# PIC32MZ1024EFK064 register map
Vendor: Microchip
Registers are 32-bit, read-write, reset 0x0 unless marked. A register's access mark holds for its fields unless they carry their own. Addresses are absolute, and some are shared; only a register's first bit layout is shown; [hi:lo] are bit positions; {n}, {i} and the like mark numbered series; 'fields as' and 'values as' point back to an identical list.

## CFG
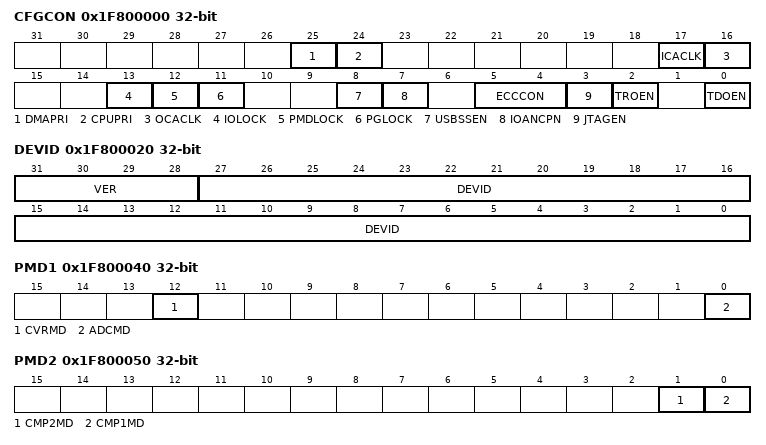
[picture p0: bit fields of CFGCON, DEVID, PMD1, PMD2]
0x1F800000 CFGCON reset not defined — (power-on value ------00------00--000--0x-1100-1)
  [25] DMAPRI, [24] CPUPRI, [17] ICACLK, [16] OCACLK, [13] IOLOCK, [12] PMDLOCK, [11] PGLOCK, [8] USBSSEN, [7] IOANCPN, [5:4] ECCCON, [3] JTAGEN, [2] TROEN, [0] TDOEN
0x1F800020 DEVID reset not defined — (power-on value 0000xxxxxxxxxxxxxxxxxxxxxxxxxxxx)
  [31:28] VER ro, [27:0] DEVID
0x1F800030 SYSKEY
0x1F800040 PMD1
  [12] CVRMD, [0] ADCMD
0x1F800050 PMD2
  [1] CMP2MD, [0] CMP1MD
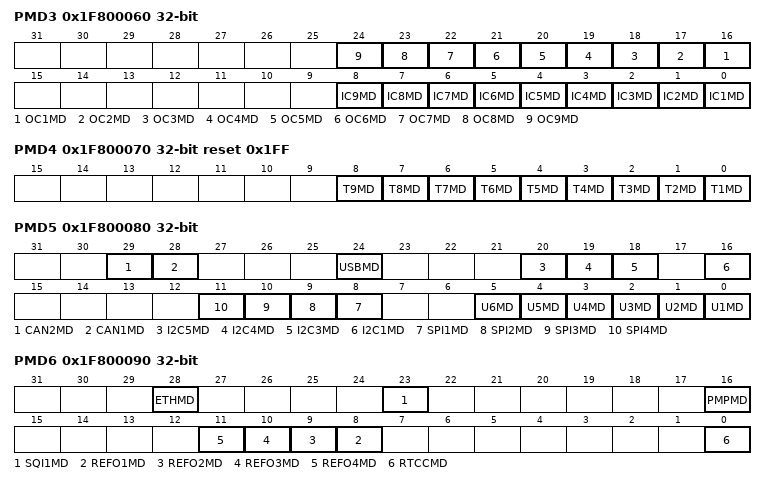
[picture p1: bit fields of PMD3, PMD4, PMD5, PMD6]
0x1F800060 PMD3
  [n+15] OC{n}MD (n=1..9), [n-1] IC{n}MD (n=1..9)
0x1F800070 PMD4 reset 0x1FF
  [n-1] T{n}MD (n=1..9)
0x1F800080 PMD5
  [29] CAN2MD, [28] CAN1MD, [24] USBMD, [20] I2C5MD, [19] I2C4MD, [18] I2C3MD, [16] I2C1MD, [n+7] SPI{n}MD (n=1..4), [n-1] U{n}MD (n=1..6)
0x1F800090 PMD6
  [28] ETHMD, [23] SQI1MD, [16] PMPMD, [n+7] REFO{n}MD (n=1..4), [0] RTCCMD
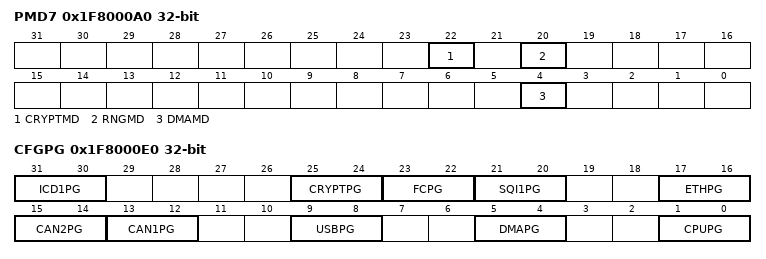
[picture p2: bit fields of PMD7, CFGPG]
0x1F8000A0 PMD7
  [22] CRYPTMD, [20] RNGMD, [4] DMAMD
0x1F8000E0 CFGPG reset not defined — (power-on value xx----000000--000000--00--00--00)
  [31:30] ICD1PG, [25:24] CRYPTPG, [23:22] FCPG, [21:20] SQI1PG, [17:16] ETHPG, [15:14] CAN2PG, [13:12] CAN1PG, [9:8] USBPG, [5:4] DMAPG, [1:0] CPUPG

## NVM
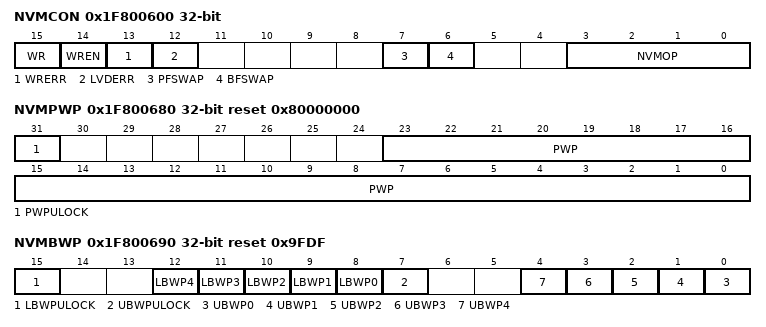
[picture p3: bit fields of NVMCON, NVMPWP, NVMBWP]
0x1F800600 NVMCON reset not defined — (power-on value ----------------0000----0x--0000)
  [15] WR, [14] WREN, [13] WRERR, [12] LVDERR, [7] PFSWAP, [6] BFSWAP, [3:0] NVMOP
0x1F800610 NVMKEY wo
0x1F800620 NVMADDR
{0x1F800630+0x10*i} NVMDATA{i} (i=0..3)
0x1F800670 NVMSRCADDR
0x1F800680 NVMPWP reset 0x80000000
  [31] PWPULOCK, [23:0] PWP
0x1F800690 NVMBWP reset 0x9FDF
  [15] LBWPULOCK, [n+8] LBWP{n} (n=0..4), [7] UBWPULOCK, [n] UBWP{n} (n=0..4)
0x1F8006A0 NVMCON2
  [7:6] SWAPLOCK

## WDT
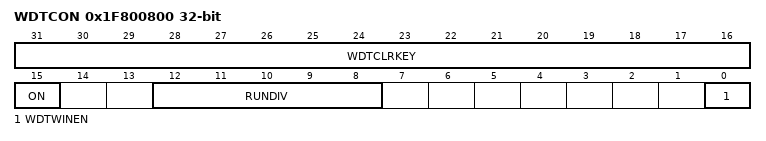
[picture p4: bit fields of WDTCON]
0x1F800800 WDTCON reset not defined — (power-on value 0000000000000000x--xxxxx-------0)
  [31:16] WDTCLRKEY wo, [15] ON, [12:8] RUNDIV ro, [0] WDTWINEN

## DMT
0x1F800A00 DMTCON
  [15] ON
0x1F800A10 DMTPRECLR
  [15:8] STEP1
0x1F800A20 DMTCLR
  [7:0] STEP2
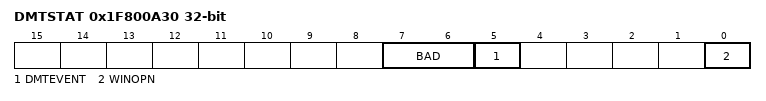
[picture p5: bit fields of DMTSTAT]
0x1F800A30 DMTSTAT ro
  [7:6] BAD, [5] DMTEVENT, [0] WINOPN
0x1F800A40 DMTCNT ro
  [31:0] COUNTER
0x1F800A60 DMTPSCNT ro reset not defined — (power-on value xxxxxxxxxxxxxxxxxxxxxxxxxxxxxxxx)
  [31:0] PSCNT
0x1F800A70 DMTPSINTV ro reset not defined — (power-on value xxxxxxxxxxxxxxxxxxxxxxxxxxxxxxxx)
  [31:0] PSINTV

## RTCC
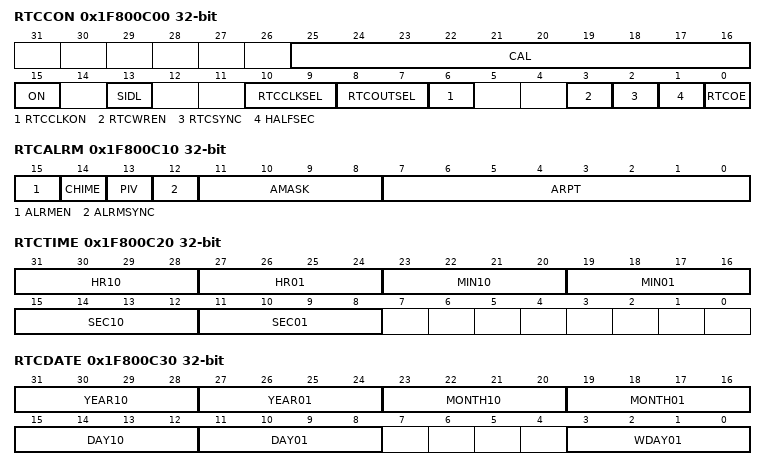
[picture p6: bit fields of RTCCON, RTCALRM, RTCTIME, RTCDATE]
0x1F800C00 RTCCON
  [25:16] CAL, [15] ON, [13] SIDL, [10:9] RTCCLKSEL, [8:7] RTCOUTSEL, [6] RTCCLKON, [3] RTCWREN, [2] RTCSYNC ro, [1] HALFSEC ro, [0] RTCOE
0x1F800C10 RTCALRM
  [15] ALRMEN, [14] CHIME, [13] PIV, [12] ALRMSYNC, [11:8] AMASK, [7:0] ARPT
0x1F800C20 RTCTIME reset not defined — (power-on value 000xxxxxxxxxxxxx0xxxxxxx--------)
  [31:28] HR10, [27:24] HR01, [23:20] MIN10, [19:16] MIN01, [15:12] SEC10, [11:8] SEC01
0x1F800C30 RTCDATE reset not defined — (power-on value xxxxxxxx000xxxxx00xxxxxx----0xxx)
  [31:28] YEAR10, [27:24] YEAR01, [23:20] MONTH10, [19:16] MONTH01, [15:12] DAY10, [11:8] DAY01, [3:0] WDAY01
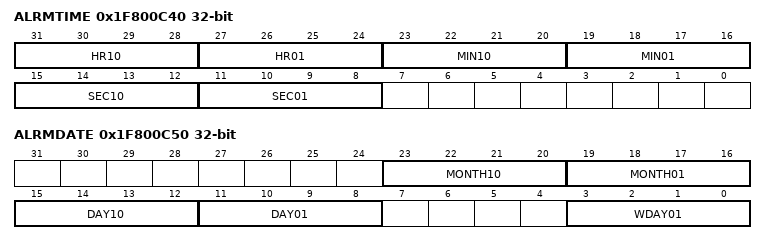
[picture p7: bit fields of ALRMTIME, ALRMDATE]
0x1F800C40 ALRMTIME reset not defined — (power-on value 000xxxxx0xxxxxxx0xxxxxxx--------)
  fields as RTCTIME
0x1F800C50 ALRMDATE reset not defined — (power-on value --------000xxxxx00xxxxxx----0xxx)
  [23:20] MONTH10, [19:16] MONTH01, [15:12] DAY10, [11:8] DAY01, [3:0] WDAY01

## CVR
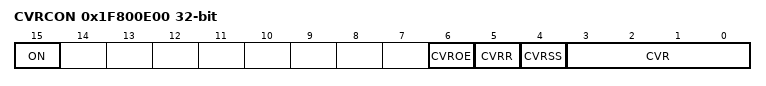
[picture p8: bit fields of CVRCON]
0x1F800E00 CVRCON
  [15] ON, [6] CVROE, [5] CVRR, [4] CVRSS, [3:0] CVR

## icd_jtag_pb
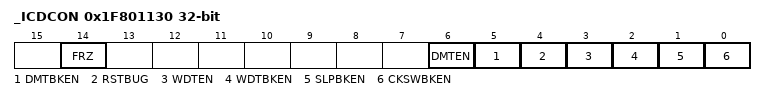
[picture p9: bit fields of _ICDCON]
0x1F801130 _ICDCON
  [14] FRZ, [6] DMTEN, [5] DMTBKEN, [4] RSTBUG, [3] WDTEN, [2] WDTBKEN, [1] SLPBKEN, [0] CKSWBKEN

## _DDPSTAT
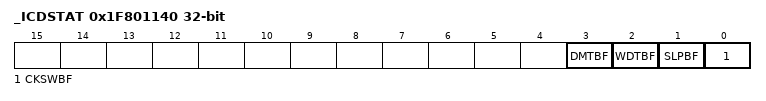
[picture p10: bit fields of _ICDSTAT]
0x1F801140 _ICDSTAT
  [3] DMTBF, [2] WDTBF, [1] SLPBF, [0] CKSWBF

## CRU
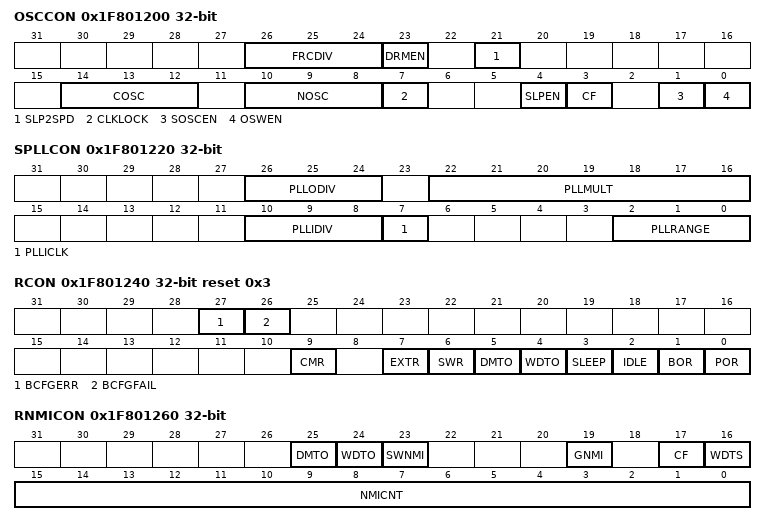
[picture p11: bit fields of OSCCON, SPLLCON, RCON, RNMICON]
0x1F801200 OSCCON reset not defined — (power-on value -----0000-x------000-xxx0--00-x0)
  [26:24] FRCDIV, [23] DRMEN, [21] SLP2SPD, [14:12] COSC ro, [10:8] NOSC, [7] CLKLOCK, [4] SLPEN, [3] CF, [1] SOSCEN, [0] OSWEN
0x1F801210 OSCTUN
  [5:0] TUN
0x1F801220 SPLLCON reset not defined — (power-on value -----001-xxxxxxx-----xxx0----xxx)
  [26:24] PLLODIV, [22:16] PLLMULT, [10:8] PLLIDIV, [7] PLLICLK, [2:0] PLLRANGE
0x1F801240 RCON reset 0x3
  [27] BCFGERR, [26] BCFGFAIL, [9] CMR, [7] EXTR, [6] SWR, [5] DMTO, [4] WDTO, [3] SLEEP, [2] IDLE, [1] BOR, [0] POR
0x1F801250 RSWRST wo
  [0] SWRST
0x1F801260 RNMICON reset not defined — (power-on value ------0x0---0-000000000000000000)
  [25] DMTO, [24] WDTO, [23] SWNMI, [19] GNMI, [17] CF, [16] WDTS, [15:0] NMICNT
0x1F801270 PWRCON
  [0] VREGS
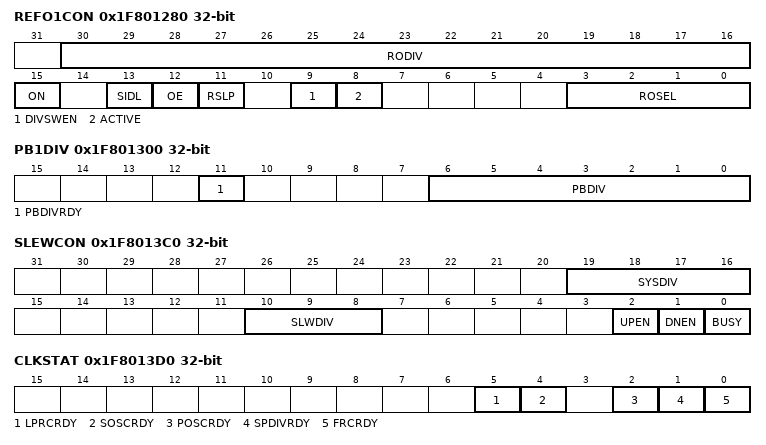
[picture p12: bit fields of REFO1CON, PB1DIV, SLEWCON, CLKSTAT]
0x1F801280 REFO1CON
  [30:16] RODIV, [15] ON, [13] SIDL, [12] OE, [11] RSLP, [9] DIVSWEN, [8] ACTIVE ro, [3:0] ROSEL
0x1F801290 REFO1TRIM
  [31:23] ROTRIM
0x1F801300 PB1DIV reset not defined — (power-on value --------------------1----xxxxxxx)
  [11] PBDIVRDY ro, [6:0] PBDIV
0x1F8013C0 SLEWCON
  [19:16] SYSDIV, [10:8] SLWDIV, [2] UPEN, [1] DNEN, [0] BUSY
0x1F8013D0 CLKSTAT reset not defined — (power-on value --------------------------00-0x0)
  [5] LPRCRDY ro, [4] SOSCRDY ro, [2] POSCRDY ro, [1] SPDIVRDY, [0] FRCRDY ro
